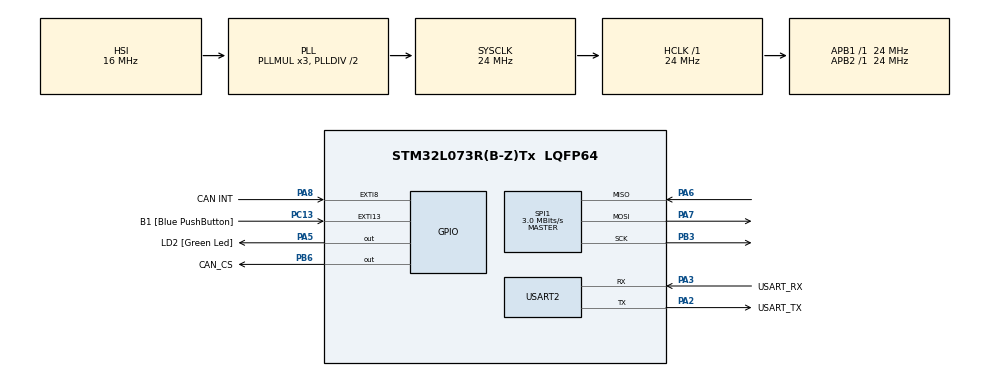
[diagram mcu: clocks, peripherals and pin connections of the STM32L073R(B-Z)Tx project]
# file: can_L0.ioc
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Mcu.Family=STM32L0
Mcu.Name=STM32L073R(B-Z)Tx
Mcu.Package=LQFP64
NVIC.EXTI4_15_IRQn=true\:0\:0\:false\:false\:true\:true\:true\:true
PA13.GPIO_Label=TMS
PA13.Mode=Serial_Wire
PA13.Signal=SYS_SWDIO
PA14.GPIO_Label=TCK
PA14.Mode=Serial_Wire
PA14.Signal=SYS_SWCLK
PA2.GPIO_Label=USART_TX
PA2.Mode=Asynchronous
PA2.Signal=USART2_TX
PA3.GPIO_Label=USART_RX
PA3.Mode=Asynchronous
PA3.Signal=USART2_RX
PA5.GPIO_Label=LD2 [Green Led]
PA5.Signal=GPIO_Output
PA6.Mode=Full_Duplex_Master
PA6.Signal=SPI1_MISO
PA7.Mode=Full_Duplex_Master
PA7.Signal=SPI1_MOSI
PA8.GPIO_Label=CAN INT
PA8.GPIO_ModeDefaultEXTI=GPIO_MODE_IT_FALLING
PA8.GPIO_PuPd=GPIO_PULLUP
PA8.Signal=GPXTI8
PB3.Mode=Full_Duplex_Master
PB3.Signal=SPI1_SCK
PB6.GPIO_Label=CAN_CS
PB6.GPIO_Speed=GPIO_SPEED_FREQ_MEDIUM
PB6.PinState=GPIO_PIN_SET
PB6.Signal=GPIO_Output
PC13.GPIO_Label=B1 [Blue PushButton]
PC13.GPIO_ModeDefaultEXTI=GPIO_MODE_IT_FALLING
PC13.Signal=GPXTI13
PC14-OSC32_IN.Mode=LSE-External-Oscillator
PC14-OSC32_IN.Signal=RCC_OSC32_IN
PC15-OSC32_OUT.Mode=LSE-External-Oscillator
PC15-OSC32_OUT.Signal=RCC_OSC32_OUT
PH0-OSC_IN.GPIO_Label=MCO
PH0-OSC_IN.Mode=HSE-External-Clock-Source
PH0-OSC_IN.Signal=RCC_OSC_IN
ProjectManager.HeapSize=0x200
ProjectManager.StackSize=0x400
ProjectManager.TargetToolchain=MDK-ARM V5.32
RCC.AHBFreq_Value=24000000
RCC.APB1Freq_Value=24000000
RCC.APB1TimFreq_Value=24000000
RCC.APB2Freq_Value=24000000
RCC.APB2TimFreq_Value=24000000
RCC.HCLKFreq_Value=24000000
RCC.HSE_VALUE=8000000
RCC.HSI16_VALUE=16000000
RCC.HSI48_VALUE=48000000
RCC.HSI_VALUE=16000000
RCC.MSI_VALUE=2097000
RCC.SYSCLKFreq_VALUE=24000000
RCC.SYSCLKSource=RCC_SYSCLKSOURCE_PLLCLK
RCC.VCOOutputFreq_Value=48000000
SPI1.BaudRatePrescaler=SPI_BAUDRATEPRESCALER_8
SPI1.CalculateBaudRate=3.0 MBits/s
SPI1.Direction=SPI_DIRECTION_2LINES
SPI1.Mode=SPI_MODE_MASTER
SPI1.VirtualType=VM_MASTER
USART2.VirtualMode-Asynchronous=VM_ASYNC
board=NUCLEO-L073RZ

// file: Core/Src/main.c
/* USER CODE BEGIN Header */
/**
  ******************************************************************************
  * @file           : main.c
  * @brief          : Main program body
  ******************************************************************************
  * @attention
  *
  * Copyright (c) 2025 STMicroelectronics.
  * All rights reserved.
  *
  * This software is licensed under terms that can be found in the LICENSE file
  * in the root directory of this software component.
  * If no LICENSE file comes with this software, it is provided AS-IS.
  *
  ******************************************************************************
  */
/* USER CODE END Header */
#include "main.h"
#include "spi.h"
#include "usart.h"
#include "gpio.h"

/* USER CODE BEGIN Includes */
#include "CANSPI.h"
#include "MCP2515.h"
/* USER CODE END Includes */

/* USER CODE BEGIN PV */

uCAN_MSG rxMessage;
/* USER CODE END PV */

void SystemClock_Config(void);

/* USER CODE BEGIN 0 */
volatile uint8_t can_rx_flag = 0;
void do_wake_up(void)
{
    HAL_GPIO_TogglePin(GPIOA, GPIO_PIN_5); // LED ON

}
void HAL_GPIO_EXTI_Callback(uint16_t GPIO_Pin)
{
	 // Set here to get filtered messege
	 if (GPIO_Pin == CAN_INT_Pin)  // PB9 INT
    {
				can_rx_flag = 1;

    }

}

/* USER CODE END 0 */

int main(void)
{

  /* MCU Configuration--------------------------------------------------------*/

  /* Reset of all peripherals, Initializes the Flash interface and the Systick. */
  HAL_Init();
	HAL_Delay(1000);

  /* Configure the system clock */
  SystemClock_Config();

  /* Initialize all configured peripherals */
  MX_GPIO_Init();
  MX_SPI1_Init();
  MX_USART2_UART_Init();
  /* USER CODE BEGIN 2 */
  CANSPI_Initialize();
	MCP2515_EnableInterrupts();

	HAL_SuspendTick();
	HAL_PWR_EnterSLEEPMode(PWR_MAINREGULATOR_ON, PWR_SLEEPENTRY_WFI);
  /* USER CODE END 2 */

  /* Infinite loop */
  while (1)
  {
  }

}

void SystemClock_Config(void)
{
  RCC_OscInitTypeDef RCC_OscInitStruct = {0};
  RCC_ClkInitTypeDef RCC_ClkInitStruct = {0};
  RCC_PeriphCLKInitTypeDef PeriphClkInit = {0};

  /** Configure the main internal regulator output voltage
  */
  __HAL_PWR_VOLTAGESCALING_CONFIG(PWR_REGULATOR_VOLTAGE_SCALE1);

  /** Initializes the RCC Oscillators according to the specified parameters
  * in the RCC_OscInitTypeDef structure.
  */
  RCC_OscInitStruct.OscillatorType = RCC_OSCILLATORTYPE_HSI;
  RCC_OscInitStruct.HSIState = RCC_HSI_ON;
  RCC_OscInitStruct.HSICalibrationValue = RCC_HSICALIBRATION_DEFAULT;
  RCC_OscInitStruct.PLL.PLLState = RCC_PLL_ON;
  RCC_OscInitStruct.PLL.PLLSource = RCC_PLLSOURCE_HSI;
  RCC_OscInitStruct.PLL.PLLMUL = RCC_PLLMUL_3;
  RCC_OscInitStruct.PLL.PLLDIV = RCC_PLLDIV_2;
  if (HAL_RCC_OscConfig(&RCC_OscInitStruct) != HAL_OK)
  {
    Error_Handler();
  }

  /** Initializes the CPU, AHB and APB buses clocks
  */
  RCC_ClkInitStruct.ClockType = RCC_CLOCKTYPE_HCLK|RCC_CLOCKTYPE_SYSCLK
                              |RCC_CLOCKTYPE_PCLK1|RCC_CLOCKTYPE_PCLK2;
  RCC_ClkInitStruct.SYSCLKSource = RCC_SYSCLKSOURCE_PLLCLK;
  RCC_ClkInitStruct.AHBCLKDivider = RCC_SYSCLK_DIV1;
  RCC_ClkInitStruct.APB1CLKDivider = RCC_HCLK_DIV1;
  RCC_ClkInitStruct.APB2CLKDivider = RCC_HCLK_DIV1;

  if (HAL_RCC_ClockConfig(&RCC_ClkInitStruct, FLASH_LATENCY_1) != HAL_OK)
  {
    Error_Handler();
  }
  PeriphClkInit.PeriphClockSelection = RCC_PERIPHCLK_USART2;
  PeriphClkInit.Usart2ClockSelection = RCC_USART2CLKSOURCE_PCLK1;
  if (HAL_RCCEx_PeriphCLKConfig(&PeriphClkInit) != HAL_OK)
  {
    Error_Handler();
  }
}

void Error_Handler(void)
{
  __disable_irq();
  while (1)
  {
  }
}
